# STM32WBA64 register map
File version: 1.0
CPU: CM33 r0p1, little endian, MPU, FPU, 4 interrupt priority bits
Registers are 32-bit, read-write, reset 0x0 unless marked. A register's access mark holds for its fields unless they carry their own. Offsets are from the block's base; [hi:lo] are bit positions; {n}, {i} and the like mark numbered series.

## CRC — CRC address block description
Base 0x40023000
Same registers: SEC_CRC 0x50023000
0x00 CRC_DR reset 0xFFFFFFFF — CRC data register
  [31:0] DR — Data register bits
0x04 CRC_IDR — CRC independent data register
  [31:0] IDR — General-purpose 32-bit data register bits
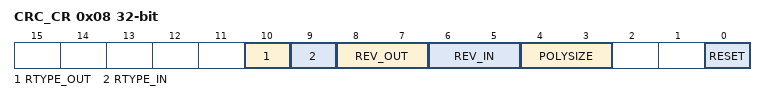
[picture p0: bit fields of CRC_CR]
0x08 CRC_CR — CRC control register
  [10] RTYPE_OUT — Reverse type output
    0=Bit level output; 1=Byte or half-word level output
  [9] RTYPE_IN — Reverse type input
    0=Bit level input; 1=Byte or half-word level input
  [8:7] REV_OUT — Reverse output data
    0=Bit order not affected (RTYPE_OUT=0 or 1); 1=Bit-reversed output format (RTYPE_OUT=0) or half-word reversal done by word (RTYPE_OUT=1); 2=Bit order not affected (RTYPE_OUT=0) or byte reversal done by word (RTYPE_OUT=1); 3=Bit order not affected (RTYPE_OUT=0 or 1)
  [6:5] REV_IN — Reverse input data
    0=Bit order not affected (RTYPE_IN=0 or 1); 1=Bit reversal done by byte (RTYPE_IN=0) or half-word reversal done by word (RTYPE_IN=1); 2=Bit reversal done by half-word (RTYPE_IN=0) or byte reversal done by word (RTYPE_IN=1); 3=Bit reversal done by word (RTYPE_IN=0) or bit order is not affected (RTYPE_IN=1)
  [4:3] POLYSIZE — Polynomial size
    0=32 bit polynomial; 1=16 bit polynomial; 2=8 bit polynomial; 3=7 bit polynomial
  [0] RESET — RESET bit
0x10 CRC_INIT reset 0xFFFFFFFF — CRC initial value
  [31:0] CRC_INIT — Programmable initial CRC value
0x14 CRC_POL reset 0x4C11DB7 — CRC polynomial
  [31:0] POL — Programmable polynomial

## GPIOA — GPIOA address block description
Base 0x42020000
Same registers: SEC_GPIOA 0x52020000
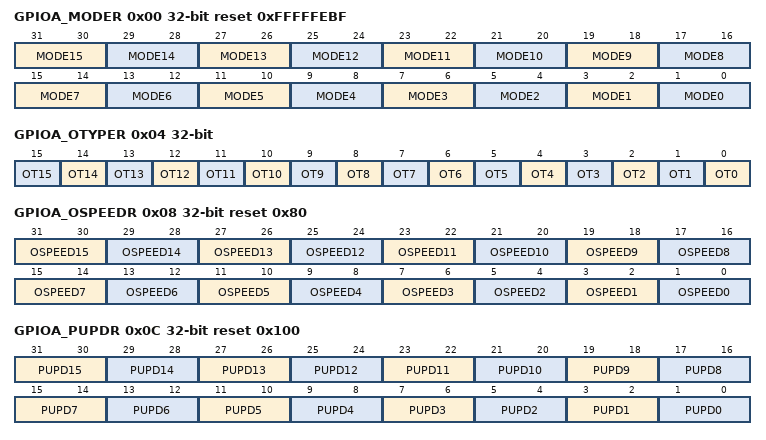
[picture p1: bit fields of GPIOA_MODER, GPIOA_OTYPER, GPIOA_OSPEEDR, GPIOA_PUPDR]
0x00 GPIOA_MODER reset 0xFFFFFEBF — GPIO port A mode register
  [31:30] MODE15 — Port configuration I/O pin 15
    0=Input mode; 1=General purpose output mode; 2=Alternate function mode; 3=Analog mode (reset state)
  [2n+1:2n] MODE{n} (n=0..14) — Port configuration I/O pin {n}
0x04 GPIOA_OTYPER — GPIO port A output type register
  [all] fields
    0=Output push-pull (reset state); 1=Output open-drain
  [n] OT{n} (n=0..15) — Port configuration I/O pin y
0x08 GPIOA_OSPEEDR reset 0x80 — GPIO port A output speed register
  [31:30] OSPEED15 — Port configuration I/O pin 15
    0=Low speed; 1=Medium speed; 2=High speed
  [2n+1:2n] OSPEED{n} (n=0..14) — Port configuration I/O pin {n}
0x0C GPIOA_PUPDR reset 0x100 — GPIO port A pull-up/pull-down register
  [31:30] PUPD15 — Port configuration I/O pin 15
    0=No pull-up, pull-down; 1=Pull-up; 2=Pull-down
  [2n+1:2n] PUPD{n} (n=0..14) — Port configuration I/O pin {n}
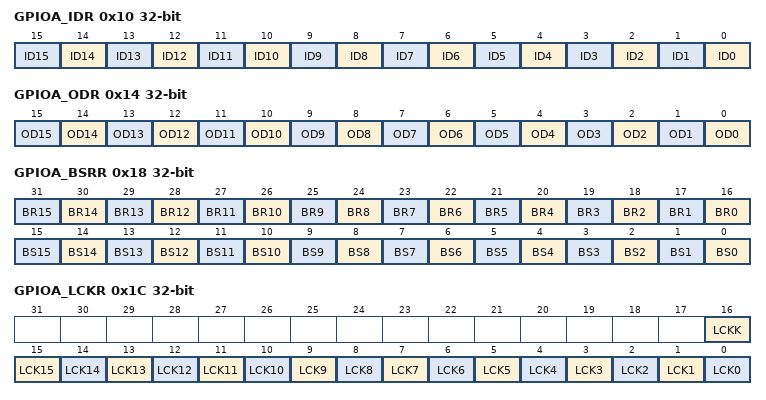
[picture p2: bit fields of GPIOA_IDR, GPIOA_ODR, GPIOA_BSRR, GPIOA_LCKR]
0x10 GPIOA_IDR ro (reset mask 0xFFFF0000) — GPIO port A input data register
  [n] ID{n} (n=0..15) — Port input data I/O pin y
0x14 GPIOA_ODR — GPIO port A output data register
  [n] OD{n} (n=0..15) — Port output data I/O pin y
0x18 GPIOA_BSRR wo — GPIO port A bit set/reset register
  [n+16] BR{n} (n=0..15) — Port reset I/O pin y
    0=No action on the corresponding ODy bit; 1=Resets the corresponding ODy bit
  [n] BS{n} (n=0..15) — Port set I/O pin y
    0=No action on the corresponding ODy bit; 1=Sets the corresponding ODy bit
0x1C GPIOA_LCKR — GPIO port A configuration lock register
  [16] LCKK — Lock key
    0=Port configuration lock key not active; 1=Port configuration lock key active
  [n] LCK{n} (n=0..15) — Port lock I/O pin y
    0=Port configuration not locked; 1=Port configuration locked
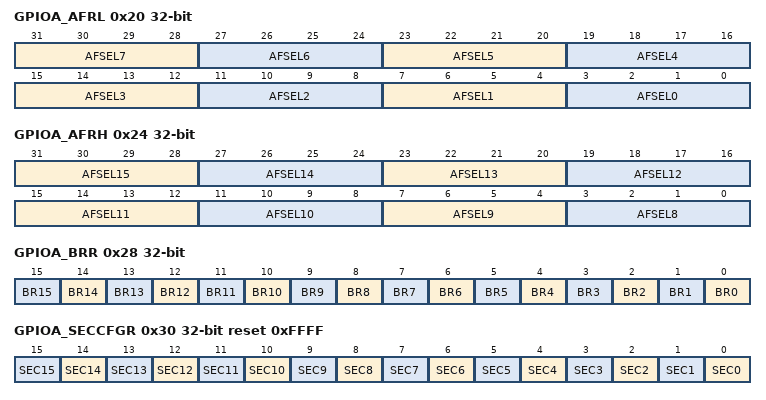
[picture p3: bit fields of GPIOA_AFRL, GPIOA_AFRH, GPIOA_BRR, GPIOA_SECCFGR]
0x20 GPIOA_AFRL — GPIO port A alternate function low register
  [31:28] AFSEL7 — Alternate function selection for port I/O pin 7
    {v}=AF{v} (v=0..15)
  [4n+3:4n] AFSEL{n} (n=0..6) — Alternate function selection for port I/O pin {n}
0x24 GPIOA_AFRH — GPIO port A alternate function high register
  [31:28] AFSEL15 — Alternate function selection for port I/O pin 15
    {v}=AF{v} (v=0..15)
  [4n-29:4n-32] AFSEL{n} (n=8..14) — Alternate function selection for port I/O pin {n}
0x28 GPIOA_BRR wo — GPIO port A bit reset register
  [all] fields
    0=No action on the corresponding ODy bit; 1=Reset the corresponding ODy bit
  [n] BR{n} (n=0..15) — Port reset I/O pin y
0x30 GPIOA_SECCFGR reset 0xFFFF — GPIO port A secure configuration register
  [all] fields
    0=The I/O pin is nonsecure; 1=The I/O pin is secure
  [n] SEC{n} (n=0..15) — I/O pin of port secure bit enable y

## Notices in the file
Copyright (c) 2025 STMicroelectronics.
SPDX-License-Identifier: Apache-2.0
Licensed under the Apache License, Version 2.0 (the "License");
you may not use this file except in compliance with the License.
You may obtain a copy of the License at
http://www.apache.org/licenses/LICENSE-2.0
Unless required by applicable law or agreed to in writing, software
distributed under the License is distributed on an "AS IS" BASIS,
WITHOUT WARRANTIES OR CONDITIONS OF ANY KIND, either express or implied.
See the License for the specific language governing permissions and
limitations under the License.
